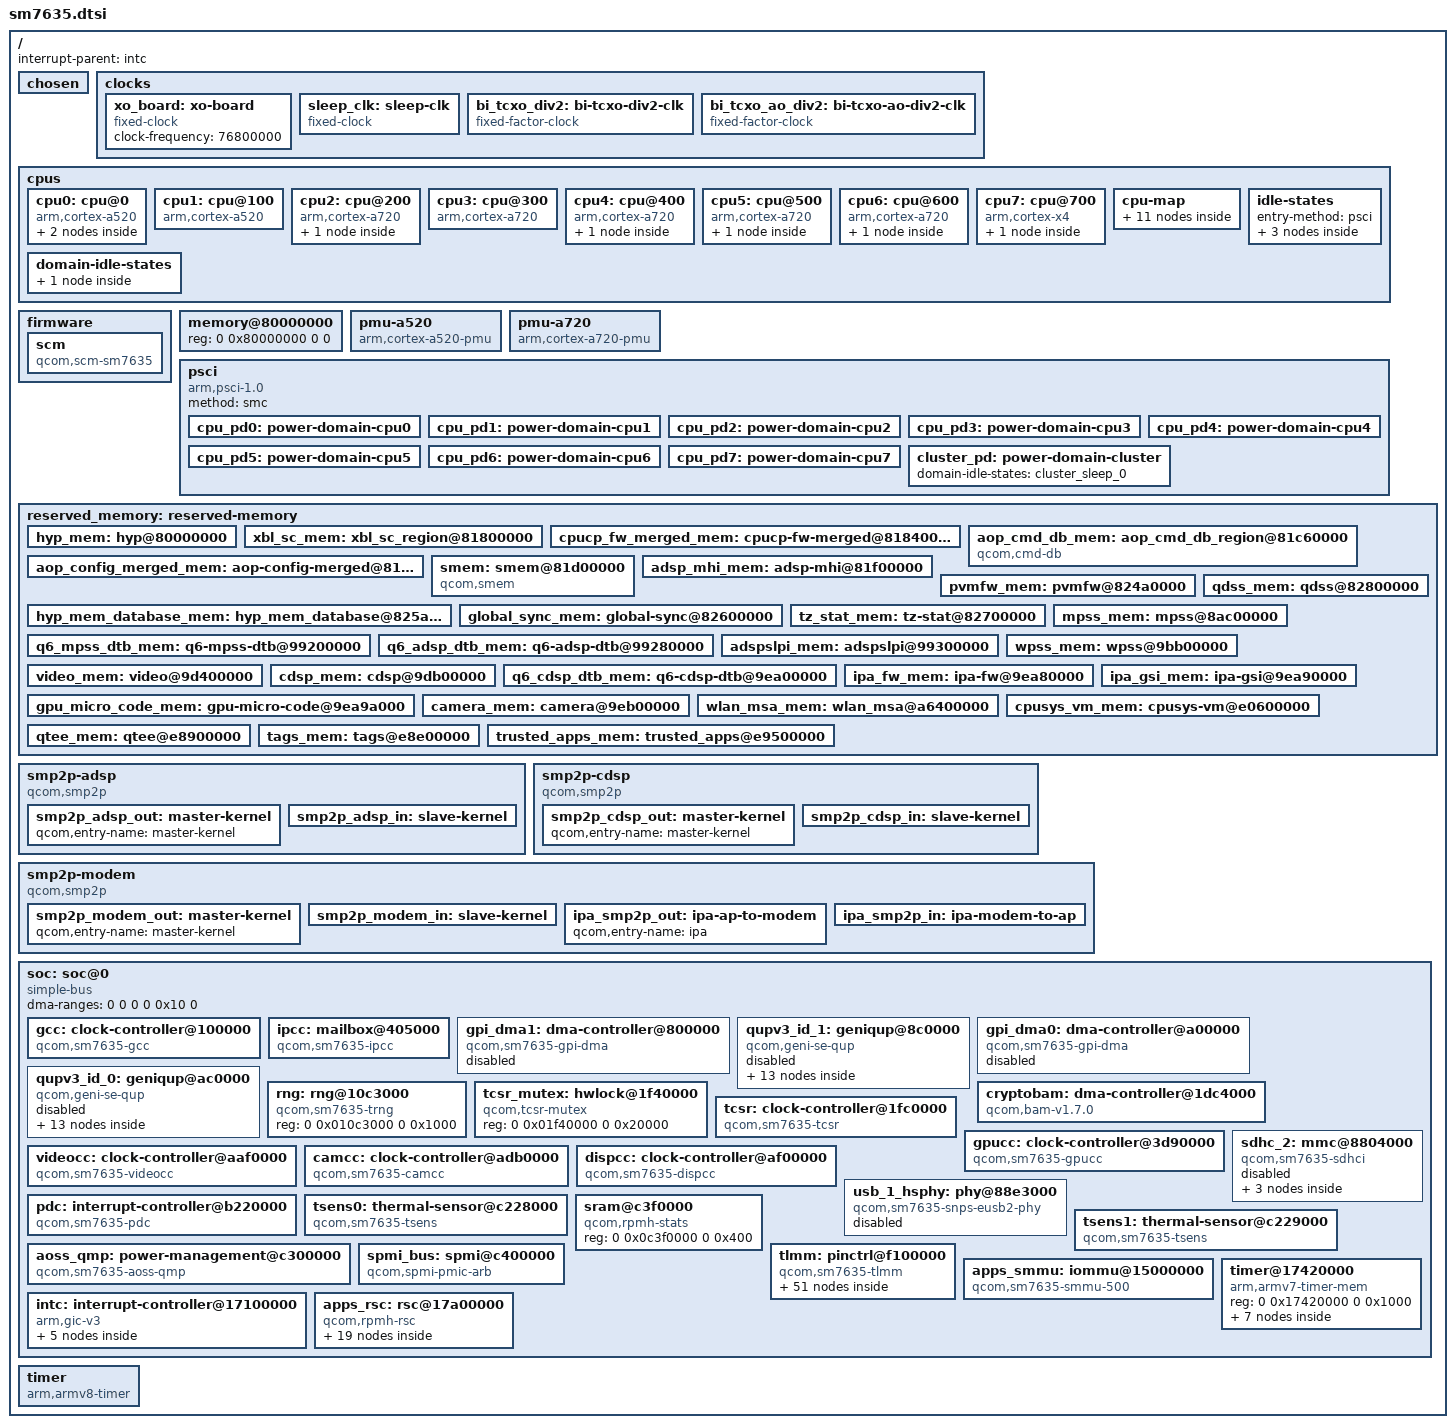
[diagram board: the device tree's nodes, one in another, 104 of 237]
// SPDX-License-Identifier: BSD-3-Clause
/*
 * Copyright (c) 2025, Danila Tikhonov <danila@jiaxyga.com>
 */

#include <dt-bindings/clock/qcom,rpmh.h>

#include <dt-bindings/clock/qcom,sm7635-gcc.h>

#include <dt-bindings/dma/qcom-gpi.h>
#include <dt-bindings/interconnect/qcom,icc.h>
#include <dt-bindings/interrupt-controller/arm-gic.h>
#include <dt-bindings/mailbox/qcom-ipcc.h>
#include <dt-bindings/power/qcom,rpmhpd.h>
#include <dt-bindings/power/qcom-rpmpd.h>
#include <dt-bindings/soc/qcom,gpr.h>
#include <dt-bindings/soc/qcom,rpmh-rsc.h>

/ {
	interrupt-parent = <&intc>;

	#address-cells = <2>;
	#size-cells = <2>;

	chosen { };

	clocks {
		xo_board: xo-board {
			compatible = "fixed-clock";
			clock-frequency = <76800000>;
			#clock-cells = <0>;
		};

		sleep_clk: sleep-clk {
			compatible = "fixed-clock";
			#clock-cells = <0>;
		};

		bi_tcxo_div2: bi-tcxo-div2-clk {
			compatible = "fixed-factor-clock";
			#clock-cells = <0>;

			clocks = <&rpmhcc RPMH_CXO_CLK>;
			clock-mult = <1>;
			clock-div = <2>;
		};

		bi_tcxo_ao_div2: bi-tcxo-ao-div2-clk {
			compatible = "fixed-factor-clock";
			#clock-cells = <0>;

			clocks = <&rpmhcc RPMH_CXO_CLK_A>;
			clock-mult = <1>;
			clock-div = <2>;
		};
	};

	cpus {
		#address-cells = <2>;
		#size-cells = <0>;

		cpu0: cpu@0 {
			device_type = "cpu";
			compatible = "arm,cortex-a520";
			reg = <0 0>;

			power-domains = <&cpu_pd0>;
			power-domain-names = "psci";

			enable-method = "psci";
			next-level-cache = <&l2_0>;

			#cooling-cells = <2>;

			l2_0: l2-cache {
				compatible = "cache";
				cache-level = <2>;
				cache-unified;
				next-level-cache = <&l3_0>;

				l3_0: l3-cache {
					compatible = "cache";
					cache-level = <3>;
					cache-unified;
				};
			};
		};

		cpu1: cpu@100 {
			device_type = "cpu";
			compatible = "arm,cortex-a520";
			reg = <0 0x100>;

			power-domains = <&cpu_pd1>;
			power-domain-names = "psci";

			enable-method = "psci";
			next-level-cache = <&l2_0>;

			//qcom,freq-domain = <&cpufreq_hw 0>;

			#cooling-cells = <2>;
		};

		cpu2: cpu@200 {
			device_type = "cpu";
			compatible = "arm,cortex-a720";
			reg = <0 0x200>;

			power-domains = <&cpu_pd2>;
			power-domain-names = "psci";

			enable-method = "psci";
			next-level-cache = <&l2_200>;

			//qcom,freq-domain = <&cpufreq_hw 3>;

			#cooling-cells = <2>;

			l2_200: l2-cache {
				compatible = "cache";
				cache-level = <2>;
				cache-unified;
				next-level-cache = <&l3_0>;
			};
		};

		cpu3: cpu@300 {
			device_type = "cpu";
			compatible = "arm,cortex-a720";
			reg = <0 0x300>;

			power-domains = <&cpu_pd3>;
			power-domain-names = "psci";

			enable-method = "psci";
			next-level-cache = <&l2_200>;

			//qcom,freq-domain = <&cpufreq_hw 3>;

			#cooling-cells = <2>;
		};

		cpu4: cpu@400 {
			device_type = "cpu";
			compatible = "arm,cortex-a720";
			reg = <0 0x400>;

			power-domains = <&cpu_pd4>;
			power-domain-names = "psci";

			enable-method = "psci";
			next-level-cache = <&l2_400>;

			//qcom,freq-domain = <&cpufreq_hw 3>;

			#cooling-cells = <2>;

			l2_400: l2-cache {
				compatible = "cache";
				cache-level = <2>;
				cache-unified;
				next-level-cache = <&l3_0>;
			};
		};

		cpu5: cpu@500 {
			device_type = "cpu";
			compatible = "arm,cortex-a720";
			reg = <0 0x500>;

			power-domains = <&cpu_pd5>;
			power-domain-names = "psci";

			enable-method = "psci";
			next-level-cache = <&l2_500>;

			//qcom,freq-domain = <&cpufreq_hw 1>;

			#cooling-cells = <2>;

			l2_500: l2-cache {
				compatible = "cache";
				cache-level = <2>;
				cache-unified;
				next-level-cache = <&l3_0>;
			};
		};

		cpu6: cpu@600 {
			device_type = "cpu";
			compatible = "arm,cortex-a720";
			reg = <0 0x600>;

			power-domains = <&cpu_pd6>;
			power-domain-names = "psci";

			enable-method = "psci";
			next-level-cache = <&l2_600>;

			//qcom,freq-domain = <&cpufreq_hw 1>;

			#cooling-cells = <2>;

			l2_600: l2-cache {
				compatible = "cache";
				cache-level = <2>;
				cache-unified;
				next-level-cache = <&l3_0>;
			};
		};

		cpu7: cpu@700 {
			device_type = "cpu";
			compatible = "arm,cortex-x4";
			reg = <0 0x700>;

			power-domains = <&cpu_pd7>;
			power-domain-names = "psci";

			enable-method = "psci";
			next-level-cache = <&l2_700>;

			//qcom,freq-domain = <&cpufreq_hw 2>;

			#cooling-cells = <2>;

			l2_700: l2-cache {
				compatible = "cache";
				cache-level = <2>;
				cache-unified;
				next-level-cache = <&l3_0>;
			};
		};

		cpu-map {
			cluster0 {
				core0 {
					cpu = <&cpu0>;
				};

				core1 {
					cpu = <&cpu1>;
				};

				core2 {
					cpu = <&cpu2>;
				};

				core3 {
					cpu = <&cpu3>;
				};
			};

			cluster1 {
				core0 {
					cpu = <&cpu4>;
				};

				core1 {
					cpu = <&cpu5>;
				};

				core2 {
					cpu = <&cpu6>;
				};
			};

			cluster2 {
				core0 {
					cpu = <&cpu7>;
				};
			};
		};

		idle-states {
			entry-method = "psci";

			silver_cpu_sleep_0: cpu-sleep-0-0 {
				compatible = "arm,idle-state";
				idle-state-name = "silver-rail-power-collapse";
				arm,psci-suspend-param = <0x40000004>;
				entry-latency-us = <550>;
				exit-latency-us = <750>;
				min-residency-us = <6700>;
				local-timer-stop;
			};

			gold_cpu_sleep_0: cpu-sleep-1-0 {
				compatible = "arm,idle-state";
				idle-state-name = "gold-rail-power-collapse";
				arm,psci-suspend-param = <0x40000004>;
				entry-latency-us = <600>;
				exit-latency-us = <1300>;
				min-residency-us = <8136>;
				local-timer-stop;
			};

			gold_plus_cpu_sleep_0: cpu-sleep-2-0 {
				compatible = "arm,idle-state";
				idle-state-name = "gold-plus-rail-power-collapse";
				arm,psci-suspend-param = <0x40000004>;
				entry-latency-us = <600>;
				exit-latency-us = <1500>;
				min-residency-us = <8551>;
				local-timer-stop;
			};
		};

		domain-idle-states {
			cluster_sleep_0: cluster-sleep-0 {
				compatible = "domain-idle-state";
				arm,psci-suspend-param = <0x41000044>;
				entry-latency-us = <750>;
				exit-latency-us = <2350>;
				min-residency-us = <9144>;
			};
		};
	};

	firmware {
		scm: scm {
			compatible = "qcom,scm-sm7635", "qcom,scm";
		};
	};

	memory@80000000 {
		device_type = "memory";
		/* We expect the bootloader to fill in the size */
		reg = <0 0x80000000 0 0>;
	};

	pmu-a520 {
		compatible = "arm,cortex-a520-pmu";
		interrupts = <GIC_PPI 7 IRQ_TYPE_LEVEL_LOW &ppi_cluster0>;
	};

	pmu-a720 {
		compatible = "arm,cortex-a720-pmu";
		interrupts = <GIC_PPI 7 IRQ_TYPE_LEVEL_LOW &ppi_cluster1>;
	};

	psci {
		compatible = "arm,psci-1.0";
		method = "smc";

		cpu_pd0: power-domain-cpu0 {
			#power-domain-cells = <0>;
			power-domains = <&cluster_pd>;
			domain-idle-states = <&silver_cpu_sleep_0>;
		};

		cpu_pd1: power-domain-cpu1 {
			#power-domain-cells = <0>;
			power-domains = <&cluster_pd>;
			domain-idle-states = <&silver_cpu_sleep_0>;
		};

		cpu_pd2: power-domain-cpu2 {
			#power-domain-cells = <0>;
			power-domains = <&cluster_pd>;
			domain-idle-states = <&silver_cpu_sleep_0>;
		};

		cpu_pd3: power-domain-cpu3 {
			#power-domain-cells = <0>;
			power-domains = <&cluster_pd>;
			domain-idle-states = <&silver_cpu_sleep_0>;
		};

		cpu_pd4: power-domain-cpu4 {
			#power-domain-cells = <0>;
			power-domains = <&cluster_pd>;
			domain-idle-states = <&gold_cpu_sleep_0>;
		};

		cpu_pd5: power-domain-cpu5 {
			#power-domain-cells = <0>;
			power-domains = <&cluster_pd>;
			domain-idle-states = <&gold_cpu_sleep_0>;
		};

		cpu_pd6: power-domain-cpu6 {
			#power-domain-cells = <0>;
			power-domains = <&cluster_pd>;
			domain-idle-states = <&gold_cpu_sleep_0>;
		};

		cpu_pd7: power-domain-cpu7 {
			#power-domain-cells = <0>;
			power-domains = <&cluster_pd>;
			domain-idle-states = <&gold_plus_cpu_sleep_0>;
		};

		cluster_pd: power-domain-cluster {
			#power-domain-cells = <0>;
			domain-idle-states = <&cluster_sleep_0>;
		};
	};

	reserved_memory: reserved-memory {
		#address-cells = <2>;
		#size-cells = <2>;
		ranges;

		hyp_mem: hyp@80000000 {
			reg = <0 0x80000000 0 0xe00000>;
			no-map;
		};

		xbl_sc_mem: xbl_sc_region@81800000 {
			reg = <0x0 0x81800000 0x0 0x40000>;
			no-map;
		};

		/*
		 * Merged regions:
		 * - cpucp_fw: 0x81840000 - 0x81a00000
		 * - xbl_dtlog: 0x81a00000 - 0x81a40000
		 * - xbl_ramdump: 0x81a40000 - 0x81c00000
		 * - aop_image:  0x81c00000 - 0x81c60000
		 */
		 cpucp_fw_merged_mem: cpucp-fw-merged@81840000 {
			reg = <0 0x81840000 0 0x420000>;
			no-map;
		};

		aop_cmd_db_mem: aop_cmd_db_region@81c60000 {
			compatible = "qcom,cmd-db";
			reg = <0 0x81c60000 0 0x20000>;
			no-map;
		};

		/*
		 * Merged regions:
		 * - aop_config: 0x81c80000 - 0x81ca0000
		 * - tme_crash_dump: 0x81ca0000 - 0x81ce0000
		 * - tme_log: 0x81ce0000 - 0x81ce4000
		 * - uefi_log: 0x81ce4000 - 0x81cf4000
		 * - chipinfo: 0x81cf4000 - 0x81cf5000
		 */
		aop_config_merged_mem: aop-config-merged@81c80000 {
			reg = <0 0x81c80000 0 0x65000>;
			no-map;
		};

		/* Secdata region can be reused by apps */

		smem: smem@81d00000 {
			compatible = "qcom,smem";
			reg = <0 0x81d00000 0 0x200000>;
			hwlocks = <&tcsr_mutex 3>;
			no-map;
		};

		adsp_mhi_mem: adsp-mhi@81f00000 {
			reg = <0 0x81f00000 0 0x20000>;
			no-map;
		};

		pvmfw_mem: pvmfw@824a0000 {
			reg = <0 0x824a0000 0 0x100000>;
			no-map;
		};

		hyp_mem_database_mem: hyp_mem_database@825a0000 {
			reg = <0 0x825a0000 0 0x60000>;
			no-map;
		};

		global_sync_mem: global-sync@82600000 {
			reg = <0 0x82600000 0 0x100000>;
			no-map;
		};

		tz_stat_mem: tz-stat@82700000 {
			reg = <0 0x82700000 0 0x100000>;
			no-map;
		};

		qdss_mem: qdss@82800000 {
			reg = <0 0x82800000 0 0x2000000>;
			no-map;
		};

		mpss_mem: mpss@8ac00000 {
			reg = <0 0x8ac00000 0 0xe600000>;
			no-map;
		};

		q6_mpss_dtb_mem: q6-mpss-dtb@99200000 {
			reg = <0 0x99200000 0 0x80000>;
			no-map;
		};

		q6_adsp_dtb_mem: q6-adsp-dtb@99280000 {
			reg = <0 0x99280000 0 0x80000>;
			no-map;
		};

		adspslpi_mem: adspslpi@99300000 {
			reg = <0 0x99300000 0 0x2800000>;
			no-map;
		};

		wpss_mem: wpss@9bb00000 {
			reg = <0 0x9bb00000 0 0x1900000>;
			no-map;
		};

		video_mem: video@9d400000 {
			reg = <0 0x9d400000 0 0x700000>;
			no-map;
		};

		cdsp_mem: cdsp@9db00000 {
			reg = <0 0x9db00000 0 0xf00000>;
			no-map;
		};

		q6_cdsp_dtb_mem: q6-cdsp-dtb@9ea00000 {
			reg = <0 0x9ea00000 0 0x80000>;
			no-map;
		};

		ipa_fw_mem: ipa-fw@9ea80000 {
			reg = <0 0x9ea80000 0 0x10000>;
			no-map;
		};

		ipa_gsi_mem: ipa-gsi@9ea90000 {
			reg = <0 0x9ea90000 0 0xa000>;
			no-map;
		};

		gpu_micro_code_mem: gpu-micro-code@9ea9a000 {
			reg = <0 0x9ea9a000 0 0x2000>;
			no-map;
		};

		camera_mem: camera@9eb00000 {
			reg = <0 0x9eb00000 0 0x800000>;
			no-map;
		};

		wlan_msa_mem: wlan_msa@a6400000 {
			reg = <0 0xa6400000 0 0xc00000>;
			no-map;
		};

		cpusys_vm_mem: cpusys-vm@e0600000 {
			reg = <0 0xe0600000 0 0x400000>;
			no-map;
		};

		qtee_mem: qtee@e8900000 {
			reg = <0 0xe8900000 0 0x500000>;
			no-map;
		};

		tags_mem: tags@e8e00000 {
			reg = <0 0xe8e00000 0 0x700000>;
			no-map;
		};

		trusted_apps_mem: trusted_apps@e9500000 {
			/* TODO: Remove me?*/
			reg = <0 0xe9500000 0 0x1200000>;
			no-map;
		};
	};

	smp2p-adsp {
		compatible = "qcom,smp2p";

		interrupts-extended = <&ipcc IPCC_CLIENT_LPASS
					     IPCC_MPROC_SIGNAL_SMP2P
					     IRQ_TYPE_EDGE_RISING>;

		mboxes = <&ipcc IPCC_CLIENT_LPASS
				IPCC_MPROC_SIGNAL_SMP2P>;

		qcom,smem = <443>, <429>;
		qcom,local-pid = <0>;
		qcom,remote-pid = <2>;

		smp2p_adsp_out: master-kernel {
			qcom,entry-name = "master-kernel";
			#qcom,smem-state-cells = <1>;
		};

		smp2p_adsp_in: slave-kernel {
			qcom,entry-name = "slave-kernel";
			interrupt-controller;
			#interrupt-cells = <2>;
		};
	};

	smp2p-cdsp {
		compatible = "qcom,smp2p";

		interrupts-extended = <&ipcc IPCC_CLIENT_CDSP
					     IPCC_MPROC_SIGNAL_SMP2P
					     IRQ_TYPE_EDGE_RISING>;

		mboxes = <&ipcc IPCC_CLIENT_CDSP
				IPCC_MPROC_SIGNAL_SMP2P>;

		qcom,smem = <94>, <432>;
		qcom,local-pid = <0>;
		qcom,remote-pid = <5>;

		smp2p_cdsp_out: master-kernel {
			qcom,entry-name = "master-kernel";
			#qcom,smem-state-cells = <1>;
		};

		smp2p_cdsp_in: slave-kernel {
			qcom,entry-name = "slave-kernel";
			interrupt-controller;
			#interrupt-cells = <2>;
		};
	};

	smp2p-modem {
		compatible = "qcom,smp2p";

		interrupts-extended = <&ipcc IPCC_CLIENT_MPSS
					     IPCC_MPROC_SIGNAL_SMP2P
					     IRQ_TYPE_EDGE_RISING>;

		mboxes = <&ipcc IPCC_CLIENT_MPSS
				IPCC_MPROC_SIGNAL_SMP2P>;

		qcom,smem = <435>, <428>;
		qcom,local-pid = <0>;
		qcom,remote-pid = <1>;

		smp2p_modem_out: master-kernel {
			qcom,entry-name = "master-kernel";
			#qcom,smem-state-cells = <1>;
		};

		smp2p_modem_in: slave-kernel {
			qcom,entry-name = "slave-kernel";
			interrupt-controller;
			#interrupt-cells = <2>;
		};

		ipa_smp2p_out: ipa-ap-to-modem {
			qcom,entry-name = "ipa";
			#qcom,smem-state-cells = <1>;
		};

		/* ipa - inbound entry from mss */
		ipa_smp2p_in: ipa-modem-to-ap {
			qcom,entry-name = "ipa";
			interrupt-controller;
			#interrupt-cells = <2>;
		};
	};

	soc: soc@0 {
		compatible = "simple-bus";

		#address-cells = <2>;
		#size-cells = <2>;
		dma-ranges = <0 0 0 0 0x10 0>;
		ranges = <0 0 0 0 0x10 0>;

		gcc: clock-controller@100000 {
			compatible = "qcom,sm7635-gcc";
			reg = <0 0x00100000 0 0x1f4200>;

			clocks = <&bi_tcxo_div2>,
				 <0>, <0>, <0>, <0>, <0>, <0>;
				 /*<&pcie0_phy QMP_PCIE_PIPE_CLK>,
				 <&pcie1_phy QMP_PCIE_PIPE_CLK>
				 <&ufs_mem_phy 0>,
				 <&ufs_mem_phy 1>,
				 <&ufs_mem_phy 2>,
				 <&usb_dp_qmpphy QMP_USB43DP_USB3_PIPE_CLK>;*/
			power-domains = <&rpmhpd RPMHPD_CX>;

			#clock-cells = <1>;
			#reset-cells = <1>;
			#power-domain-cells = <1>;
		};

		ipcc: mailbox@405000 {
			compatible = "qcom,sm7635-ipcc",
				     "qcom,ipcc";
			reg = <0 0x00405000 0 0x1000>;

			interrupts = <GIC_SPI 229 IRQ_TYPE_LEVEL_HIGH 0>;
			interrupt-controller;
			#interrupt-cells = <3>;

			#mbox-cells = <2>;
		};

		gpi_dma1: dma-controller@800000 {
			compatible = "qcom,sm7635-gpi-dma",
				     "qcom,sm6350-gpi-dma";
			reg = <0 0x00800000 0 0x60000>;

			interrupts = <GIC_SPI 588 IRQ_TYPE_LEVEL_HIGH 0>,
				     <GIC_SPI 589 IRQ_TYPE_LEVEL_HIGH 0>,
				     <GIC_SPI 590 IRQ_TYPE_LEVEL_HIGH 0>,
				     <GIC_SPI 591 IRQ_TYPE_LEVEL_HIGH 0>,
				     <GIC_SPI 592 IRQ_TYPE_LEVEL_HIGH 0>,
				     <GIC_SPI 593 IRQ_TYPE_LEVEL_HIGH 0>,
				     <GIC_SPI 594 IRQ_TYPE_LEVEL_HIGH 0>,
				     <GIC_SPI 595 IRQ_TYPE_LEVEL_HIGH 0>,
				     <GIC_SPI 351 IRQ_TYPE_LEVEL_HIGH 0>,
				     <GIC_SPI 352 IRQ_TYPE_LEVEL_HIGH 0>,
				     <GIC_SPI 353 IRQ_TYPE_LEVEL_HIGH 0>,
				     <GIC_SPI 354 IRQ_TYPE_LEVEL_HIGH 0>,
				     <GIC_SPI 355 IRQ_TYPE_LEVEL_HIGH 0>;

			dma-channels = <12>;
			dma-channel-mask = <0x3f>;
			#dma-cells = <3>;

			iommus = <&apps_smmu 0x36 0>;

			dma-coherent;

			status = "disabled";
		};

		qupv3_id_1: geniqup@8c0000 {
			compatible = "qcom,geni-se-qup";
			reg = <0 0x008c0000 0 0x2000>;

			clocks = <&gcc GCC_QUPV3_WRAP_1_M_AHB_CLK>,
				 <&gcc GCC_QUPV3_WRAP_1_S_AHB_CLK>;
			clock-names = "m-ahb",
				      "s-ahb";

			iommus = <&apps_smmu 0x23 0>;

			dma-coherent;

			#address-cells = <2>;
			#size-cells = <2>;
			ranges;

			status = "disabled";

			i2c7: i2c@880000 {
				compatible = "qcom,geni-i2c";
				reg = <0 0x00880000 0 0x4000>;

				interrupts = <GIC_SPI 373 IRQ_TYPE_LEVEL_HIGH 0>;

				clocks = <&gcc GCC_QUPV3_WRAP1_S0_CLK>;
				clock-names = "se";

				/* TODO: Interconnects */

				power-domains = <&rpmhpd RPMHPD_CX>;

				/* TODO: operating-points-v2 */

				dmas = <&gpi_dma1 0 0 QCOM_GPI_I2C>,
				       <&gpi_dma1 1 0 QCOM_GPI_I2C>;
				dma-names = "tx",
					    "rx";

				pinctrl-0 = <&qup_i2c7_data_clk>;
				pinctrl-names = "default";

				#address-cells = <1>;
				#size-cells = <0>;

				status = "disabled";
			};

			spi7: spi@880000 {
				compatible = "qcom,geni-spi";
				reg = <0 0x00880000 0 0x4000>;

				interrupts = <GIC_SPI 373 IRQ_TYPE_LEVEL_HIGH 0>;

				clocks = <&gcc GCC_QUPV3_WRAP1_S0_CLK>;
				clock-names = "se";

				/* TODO: Interconnects */

				power-domains = <&rpmhpd RPMHPD_CX>;

				/* TODO: operating-points-v2 */

				dmas = <&gpi_dma1 0 0 QCOM_GPI_SPI>,
				       <&gpi_dma1 1 0 QCOM_GPI_SPI>;
				dma-names = "tx",
					    "rx";

				pinctrl-0 = <&qup_spi7_data_clk>,
					    <&qup_spi7_cs>;
				pinctrl-names = "default";

				#address-cells = <1>;
				#size-cells = <0>;

				status = "disabled";
			};

			i2c8: i2c@884000 {
				compatible = "qcom,geni-i2c";
				reg = <0 0x00884000 0 0x4000>;

				interrupts = <GIC_SPI 583 IRQ_TYPE_LEVEL_HIGH 0>;

				clocks = <&gcc GCC_QUPV3_WRAP1_S1_CLK>;
				clock-names = "se";

				/* TODO: Interconnects */

				power-domains = <&rpmhpd RPMHPD_CX>;

				/* TODO: operating-points-v2 */

				dmas = <&gpi_dma1 0 1 QCOM_GPI_I2C>,
				       <&gpi_dma1 1 1 QCOM_GPI_I2C>;
				dma-names = "tx",
					    "rx";

				pinctrl-0 = <&qup_i2c8_data_clk>;
				pinctrl-names = "default";

				#address-cells = <1>;
				#size-cells = <0>;

				status = "disabled";
			};

			spi8: spi@884000 {
				compatible = "qcom,geni-spi";
				reg = <0 0x00884000 0 0x4000>;

				interrupts = <GIC_SPI 583 IRQ_TYPE_LEVEL_HIGH 0>;

				clocks = <&gcc GCC_QUPV3_WRAP1_S1_CLK>;
				clock-names = "se";

				/* TODO: Interconnects */

				power-domains = <&rpmhpd RPMHPD_CX>;

				/* TODO: operating-points-v2 */

				dmas = <&gpi_dma1 0 1 QCOM_GPI_SPI>,
				       <&gpi_dma1 1 1 QCOM_GPI_SPI>;
				dma-names = "tx",
					    "rx";

				pinctrl-0 = <&qup_spi8_data_clk>,
					    <&qup_spi8_cs>;
				pinctrl-names = "default";

				#address-cells = <1>;
				#size-cells = <0>;

				status = "disabled";
			};

			i2c9: i2c@888000 {
				compatible = "qcom,geni-i2c";
				reg = <0 0x00888000 0 0x4000>;

				interrupts = <GIC_SPI 584 IRQ_TYPE_LEVEL_HIGH 0>;

				clocks = <&gcc GCC_QUPV3_WRAP1_S2_CLK>;
				clock-names = "se";

				/* TODO: Interconnects */

				power-domains = <&rpmhpd RPMHPD_CX>;

				/* TODO: operating-points-v2 */

				dmas = <&gpi_dma1 0 2 QCOM_GPI_I2C>,
				       <&gpi_dma1 1 2 QCOM_GPI_I2C>;
				dma-names = "tx",
					    "rx";

				pinctrl-0 = <&qup_i2c9_data_clk>;
				pinctrl-names = "default";

				#address-cells = <1>;
				#size-cells = <0>;

				status = "disabled";
			};

			spi9: spi@888000 {
				compatible = "qcom,geni-spi";
				reg = <0 0x00888000 0 0x4000>;

				interrupts = <GIC_SPI 584 IRQ_TYPE_LEVEL_HIGH 0>;

				clocks = <&gcc GCC_QUPV3_WRAP1_S2_CLK>;
				clock-names = "se";

				/* TODO: Interconnects */

				power-domains = <&rpmhpd RPMHPD_CX>;

				/* TODO: operating-points-v2 */

				dmas = <&gpi_dma1 0 2 QCOM_GPI_SPI>,
				       <&gpi_dma1 1 2 QCOM_GPI_SPI>;
				dma-names = "tx",
					    "rx";

				pinctrl-0 = <&qup_spi9_data_clk>,
					    <&qup_spi9_cs>;
				pinctrl-names = "default";

				#address-cells = <1>;
				#size-cells = <0>;

				status = "disabled";
			};

			i2c10: i2c@88c000 {
				compatible = "qcom,geni-i2c";
				reg = <0 0x0088c000 0 0x4000>;

				interrupts = <GIC_SPI 585 IRQ_TYPE_LEVEL_HIGH 0>;

				clocks = <&gcc GCC_QUPV3_WRAP1_S3_CLK>;
				clock-names = "se";

				/* TODO: Interconnects */

				power-domains = <&rpmhpd RPMHPD_CX>;

				/* TODO: operating-points-v2 */

				dmas = <&gpi_dma1 0 3 QCOM_GPI_I2C>,
				       <&gpi_dma1 1 3 QCOM_GPI_I2C>;
				dma-names = "tx",
					    "rx";

				pinctrl-0 = <&qup_i2c10_data_clk>;
				pinctrl-names = "default";

				#address-cells = <1>;
				#size-cells = <0>;

				status = "disabled";
			};

			spi10: spi@88c000 {
				compatible = "qcom,geni-spi";
				reg = <0 0x0088c000 0 0x4000>;

				interrupts = <GIC_SPI 585 IRQ_TYPE_LEVEL_HIGH 0>;

				clocks = <&gcc GCC_QUPV3_WRAP1_S3_CLK>;
				clock-names = "se";

				/* TODO: Interconnects */

				power-domains = <&rpmhpd RPMHPD_CX>;

				/* TODO: operating-points-v2 */

				dmas = <&gpi_dma1 0 3 QCOM_GPI_SPI>,
				       <&gpi_dma1 1 3 QCOM_GPI_SPI>;
				dma-names = "tx",
					    "rx";

				pinctrl-0 = <&qup_spi10_data_clk>,
					    <&qup_spi10_cs>;
				pinctrl-names = "default";

				#address-cells = <1>;
				#size-cells = <0>;

				status = "disabled";
			};

			uart11: serial@890000 {
				compatible = "qcom,geni-uart";
				reg = <0 0x00890000 0 0x4000>;

				interrupts = <GIC_SPI 586 IRQ_TYPE_LEVEL_HIGH 0>;

				clocks = <&gcc GCC_QUPV3_WRAP1_S4_CLK>;
				clock-names = "se";

				/* TODO: Interconnects */

				power-domains = <&rpmhpd RPMHPD_CX>;

				/* TODO: operating-points-v2 */

				pinctrl-0 = <&qup_uart11_default>,
					    <&qup_uart11_cts_rts>;
				pinctrl-names = "default";

				status = "disabled";
			};

			i2c12: i2c@894000 {
				compatible = "qcom,geni-i2c";
				reg = <0 0x00894000 0 0x4000>;

				interrupts = <GIC_SPI 587 IRQ_TYPE_LEVEL_HIGH 0>;

				clocks = <&gcc GCC_QUPV3_WRAP1_S5_CLK>;
				clock-names = "se";

				/* TODO: Interconnects */

				power-domains = <&rpmhpd RPMHPD_CX>;

				/* TODO: operating-points-v2 */

				dmas = <&gpi_dma1 0 5 QCOM_GPI_I2C>,
				       <&gpi_dma1 1 5 QCOM_GPI_I2C>;
				dma-names = "tx",
					    "rx";

				pinctrl-0 = <&qup_i2c12_data_clk>;
				pinctrl-names = "default";

				#address-cells = <1>;
				#size-cells = <0>;

				status = "disabled";
			};

			spi12: spi@894000 {
				compatible = "qcom,geni-spi";
				reg = <0 0x00894000 0 0x4000>;

				interrupts = <GIC_SPI 587 IRQ_TYPE_LEVEL_HIGH 0>;

				clocks = <&gcc GCC_QUPV3_WRAP1_S5_CLK>;
				clock-names = "se";

				/* TODO: Interconnects */

				power-domains = <&rpmhpd RPMHPD_CX>;

				/* TODO: operating-points-v2 */

				dmas = <&gpi_dma1 0 5 QCOM_GPI_SPI>,
				       <&gpi_dma1 1 5 QCOM_GPI_SPI>;
				dma-names = "tx",
					    "rx";

				pinctrl-0 = <&qup_spi12_data_clk>,
					    <&qup_spi12_cs>;
				pinctrl-names = "default";

				#address-cells = <1>;
				#size-cells = <0>;

				status = "disabled";
			};

			i2c13: i2c@898000 {
				compatible = "qcom,geni-i2c";
				reg = <0 0x00898000 0 0x4000>;

				interrupts = <GIC_SPI 461 IRQ_TYPE_LEVEL_HIGH 0>;

				clocks = <&gcc GCC_QUPV3_WRAP1_S6_CLK>;
				clock-names = "se";

				/* TODO: Interconnects */

				power-domains = <&rpmhpd RPMHPD_CX>;

				/* TODO: operating-points-v2 */

				dmas = <&gpi_dma1 0 6 QCOM_GPI_I2C>,
				       <&gpi_dma1 1 6 QCOM_GPI_I2C>;
				dma-names = "tx",
					    "rx";

				pinctrl-0 = <&qup_i2c13_data_clk>;
				pinctrl-names = "default";

				#address-cells = <1>;
				#size-cells = <0>;

				status = "disabled";
			};

			spi13: spi@898000 {
				compatible = "qcom,geni-spi";
				reg = <0 0x00898000 0 0x4000>;

				interrupts = <GIC_SPI 461 IRQ_TYPE_LEVEL_HIGH 0>;

				clocks = <&gcc GCC_QUPV3_WRAP1_S6_CLK>;
				clock-names = "se";

				/* TODO: Interconnects */

				power-domains = <&rpmhpd RPMHPD_CX>;

				/* TODO: operating-points-v2 */

				dmas = <&gpi_dma1 0 6 QCOM_GPI_SPI>,
				       <&gpi_dma1 1 6 QCOM_GPI_SPI>;
				dma-names = "tx",
					    "rx";

				pinctrl-0 = <&qup_spi13_data_clk>,
					    <&qup_spi13_cs>;
				pinctrl-names = "default";

				#address-cells = <1>;
				#size-cells = <0>;

				status = "disabled";
			};
		};

		gpi_dma0: dma-controller@a00000 {
			compatible = "qcom,sm7635-gpi-dma",
				     "qcom,sm6350-gpi-dma";
			reg = <0 0x00a00000 0 0x60000>;

			interrupts = <GIC_SPI 433 IRQ_TYPE_LEVEL_HIGH 0>,
				     <GIC_SPI 434 IRQ_TYPE_LEVEL_HIGH 0>,
				     <GIC_SPI 435 IRQ_TYPE_LEVEL_HIGH 0>,
				     <GIC_SPI 436 IRQ_TYPE_LEVEL_HIGH 0>,
				     <GIC_SPI 437 IRQ_TYPE_LEVEL_HIGH 0>,
				     <GIC_SPI 438 IRQ_TYPE_LEVEL_HIGH 0>,
				     <GIC_SPI 439 IRQ_TYPE_LEVEL_HIGH 0>,
				     <GIC_SPI 595 IRQ_TYPE_LEVEL_HIGH 0>,
				     <GIC_SPI 596 IRQ_TYPE_LEVEL_HIGH 0>,
				     <GIC_SPI 597 IRQ_TYPE_LEVEL_HIGH 0>,
				     <GIC_SPI 598 IRQ_TYPE_LEVEL_HIGH 0>,
				     <GIC_SPI 599 IRQ_TYPE_LEVEL_HIGH 0>;

			dma-channels = <12>;
			dma-channel-mask = <0x3e>;
			#dma-cells = <3>;

			iommus = <&apps_smmu 0x576 0>;

			dma-coherent;

			status = "disabled";
		};

		qupv3_id_0: geniqup@ac0000 {
			compatible = "qcom,geni-se-qup";
			reg = <0 0x00ac0000 0 0x2000>;

			clocks = <&gcc GCC_QUPV3_WRAP_0_M_AHB_CLK>,
				 <&gcc GCC_QUPV3_WRAP_0_S_AHB_CLK>;
			clock-names = "m-ahb",
				      "s-ahb";

			/* TODO: Interconnects */

			iommus = <&apps_smmu 0x563 0>;

			dma-coherent;

			#address-cells = <2>;
			#size-cells = <2>;
			ranges;

			status = "disabled";

			i2c0: i2c@a80000 {
				compatible = "qcom,geni-i2c";
				reg = <0 0x00a80000 0 0x4000>;

				interrupts = <GIC_SPI 520 IRQ_TYPE_LEVEL_HIGH 0>;

				clocks = <&gcc GCC_QUPV3_WRAP0_S0_CLK>;
				clock-names = "se";

				/* TODO: Interconnects */

				power-domains = <&rpmhpd RPMHPD_CX>;

				/* TODO: operating-points-v2 */

				dmas = <&gpi_dma0 0 0 QCOM_GPI_I2C>,
				       <&gpi_dma0 1 0 QCOM_GPI_I2C>;
				dma-names = "tx",
					    "rx";

				pinctrl-0 = <&qup_i2c0_data_clk>;
				pinctrl-names = "default";

				#address-cells = <1>;
				#size-cells = <0>;

				status = "disabled";
			};

			spi0: spi@a80000 {
				compatible = "qcom,geni-spi";
				reg = <0 0x00a80000 0 0x4000>;

				interrupts = <GIC_SPI 520 IRQ_TYPE_LEVEL_HIGH 0>;

				clocks = <&gcc GCC_QUPV3_WRAP0_S0_CLK>;
				clock-names = "se";

				/* TODO: Interconnects */

				power-domains = <&rpmhpd RPMHPD_CX>;

				/* TODO: operating-points-v2 */

				dmas = <&gpi_dma0 0 0 QCOM_GPI_SPI>,
				       <&gpi_dma0 1 0 QCOM_GPI_SPI>;
				dma-names = "tx",
					    "rx";

				pinctrl-0 = <&qup_spi0_data_clk>,
					    <&qup_spi0_cs>;
				pinctrl-names = "default";

				#address-cells = <1>;
				#size-cells = <0>;

				status = "disabled";
			};

			i2c1: i2c@a84000 {
				compatible = "qcom,geni-i2c";
				reg = <0 0x00a84000 0 0x4000>;

				interrupts = <GIC_SPI 521 IRQ_TYPE_LEVEL_HIGH 0>;

				clocks = <&gcc GCC_QUPV3_WRAP0_S1_CLK>;
				clock-names = "se";

				/* TODO: Interconnects */

				power-domains = <&rpmhpd RPMHPD_CX>;

				/* TODO: operating-points-v2 */

				dmas = <&gpi_dma0 0 1 QCOM_GPI_I2C>,
				       <&gpi_dma0 1 1 QCOM_GPI_I2C>;
				dma-names = "tx",
					    "rx";

				pinctrl-0 = <&qup_i2c1_data_clk>;
				pinctrl-names = "default";

				#address-cells = <1>;
				#size-cells = <0>;

				status = "disabled";
			};

			spi1: spi@a84000 {
				compatible = "qcom,geni-spi";
				reg = <0 0x00a84000 0 0x4000>;

				interrupts = <GIC_SPI 521 IRQ_TYPE_LEVEL_HIGH 0>;

				clocks = <&gcc GCC_QUPV3_WRAP0_S1_CLK>;
				clock-names = "se";

				/* TODO: Interconnects */

				power-domains = <&rpmhpd RPMHPD_CX>;

				/* TODO: operating-points-v2 */

				dmas = <&gpi_dma0 0 1 QCOM_GPI_SPI>,
				       <&gpi_dma0 1 1 QCOM_GPI_SPI>;
				dma-names = "tx",
					    "rx";

				pinctrl-0 = <&qup_spi1_data_clk>,
					    <&qup_spi1_cs>;
				pinctrl-names = "default";

				#address-cells = <1>;
				#size-cells = <0>;

				status = "disabled";
			};

			i2c2: i2c@a88000 {
				compatible = "qcom,geni-i2c";
				reg = <0 0x00a88000 0 0x4000>;

				interrupts = <GIC_SPI 522 IRQ_TYPE_LEVEL_HIGH 0>;

				clocks = <&gcc GCC_QUPV3_WRAP0_S2_CLK>;
				clock-names = "se";

				/* TODO: Interconnects */

				power-domains = <&rpmhpd RPMHPD_CX>;

				/* TODO: operating-points-v2 */

				dmas = <&gpi_dma0 0 2 QCOM_GPI_I2C>,
				       <&gpi_dma0 1 2 QCOM_GPI_I2C>;
				dma-names = "tx",
					    "rx";

				pinctrl-0 = <&qup_i2c2_data_clk>;
				pinctrl-names = "default";

				#address-cells = <1>;
				#size-cells = <0>;

				status = "disabled";
			};

			spi2: spi@a88000 {
				compatible = "qcom,geni-spi";
				reg = <0 0x00a88000 0 0x4000>;

				interrupts = <GIC_SPI 522 IRQ_TYPE_LEVEL_HIGH 0>;

				clocks = <&gcc GCC_QUPV3_WRAP0_S2_CLK>;
				clock-names = "se";

				/* TODO: Interconnects */

				power-domains = <&rpmhpd RPMHPD_CX>;

				/* TODO: operating-points-v2 */

				dmas = <&gpi_dma0 0 2 QCOM_GPI_SPI>,
				       <&gpi_dma0 1 2 QCOM_GPI_SPI>;
				dma-names = "tx",
					    "rx";

				pinctrl-0 = <&qup_spi2_data_clk>,
					    <&qup_spi2_cs>;
				pinctrl-names = "default";

				#address-cells = <1>;
				#size-cells = <0>;

				status = "disabled";
			};

			i2c3: i2c@a8c000 {
				compatible = "qcom,geni-i2c";
				reg = <0 0x00a8c000 0 0x4000>;

				interrupts = <GIC_SPI 523 IRQ_TYPE_LEVEL_HIGH 0>;

				clocks = <&gcc GCC_QUPV3_WRAP0_S3_CLK>;
				clock-names = "se";

				/* TODO: Interconnects */

				power-domains = <&rpmhpd RPMHPD_CX>;

				/* TODO: operating-points-v2 */

				dmas = <&gpi_dma0 0 3 QCOM_GPI_I2C>,
				       <&gpi_dma0 1 3 QCOM_GPI_I2C>;
				dma-names = "tx",
					    "rx";

				pinctrl-0 = <&qup_i2c3_data_clk>;
				pinctrl-names = "default";

				#address-cells = <1>;
				#size-cells = <0>;

				status = "disabled";
			};

			spi3: spi@a8c000 {
				compatible = "qcom,geni-spi";
				reg = <0 0x00a8c000 0 0x4000>;

				interrupts = <GIC_SPI 523 IRQ_TYPE_LEVEL_HIGH 0>;

				clocks = <&gcc GCC_QUPV3_WRAP0_S3_CLK>;
				clock-names = "se";

				/* TODO: Interconnects */

				power-domains = <&rpmhpd RPMHPD_CX>;

				/* TODO: operating-points-v2 */

				dmas = <&gpi_dma0 0 3 QCOM_GPI_SPI>,
				       <&gpi_dma0 1 3 QCOM_GPI_SPI>;
				dma-names = "tx",
					    "rx";

				pinctrl-0 = <&qup_spi3_data_clk>,
					    <&qup_spi3_cs>;
				pinctrl-names = "default";

				#address-cells = <1>;
				#size-cells = <0>;

				status = "disabled";
			};

			i2c4: i2c@a90000 {
				compatible = "qcom,geni-i2c";
				reg = <0 0x00a90000 0 0x4000>;

				interrupts = <GIC_SPI 524 IRQ_TYPE_LEVEL_HIGH 0>;

				clocks = <&gcc GCC_QUPV3_WRAP0_S4_CLK>;
				clock-names = "se";

				/* TODO: Interconnects */

				power-domains = <&rpmhpd RPMHPD_CX>;

				/* TODO: operating-points-v2 */

				dmas = <&gpi_dma0 0 4 QCOM_GPI_I2C>,
				       <&gpi_dma0 1 4 QCOM_GPI_I2C>;
				dma-names = "tx",
					    "rx";

				pinctrl-0 = <&qup_i2c4_data_clk>;
				pinctrl-names = "default";

				#address-cells = <1>;
				#size-cells = <0>;

				status = "disabled";
			};

			spi4: spi@a90000 {
				compatible = "qcom,geni-spi";
				reg = <0 0x00a90000 0 0x4000>;

				interrupts = <GIC_SPI 524 IRQ_TYPE_LEVEL_HIGH 0>;

				clocks = <&gcc GCC_QUPV3_WRAP0_S4_CLK>;
				clock-names = "se";

				/* TODO: Interconnects */

				power-domains = <&rpmhpd RPMHPD_CX>;

				/* TODO: operating-points-v2 */

				dmas = <&gpi_dma0 0 4 QCOM_GPI_SPI>,
				       <&gpi_dma0 1 4 QCOM_GPI_SPI>;
				dma-names = "tx",
					    "rx";

				pinctrl-0 = <&qup_spi4_data_clk>,
					    <&qup_spi4_cs>;
				pinctrl-names = "default";

				#address-cells = <1>;
				#size-cells = <0>;

				status = "disabled";
			};

			uart5: serial@a94000 {
				compatible = "qcom,geni-uart";
				reg = <0 0x00a94000 0 0x4000>;

				interrupts = <GIC_SPI 525 IRQ_TYPE_LEVEL_HIGH 0>;

				clocks = <&gcc GCC_QUPV3_WRAP0_S5_CLK>;
				clock-names = "se";

				/* TODO: Interconnects */

				power-domains = <&rpmhpd RPMHPD_CX>;

				/* TODO: operating-points-v2 */

				pinctrl-0 = <&qup_uart5_default>;
				pinctrl-names = "default";

				status = "disabled";
			};

			i2c6: i2c@a98000 {
				compatible = "qcom,geni-i2c";
				reg = <0 0x00a98000 0 0x4000>;

				interrupts = <GIC_SPI 526 IRQ_TYPE_LEVEL_HIGH 0>;

				clocks = <&gcc GCC_QUPV3_WRAP0_S6_CLK>;
				clock-names = "se";

				/* TODO: Interconnects */

				power-domains = <&rpmhpd RPMHPD_CX>;

				/* TODO: operating-points-v2 */

				dmas = <&gpi_dma0 0 6 QCOM_GPI_I2C>,
				       <&gpi_dma0 1 6 QCOM_GPI_I2C>;
				dma-names = "tx",
					    "rx";

				pinctrl-0 = <&qup_i2c6_data_clk>;
				pinctrl-names = "default";

				#address-cells = <1>;
				#size-cells = <0>;

				status = "disabled";
			};

			spi6: spi@a98000 {
				compatible = "qcom,geni-spi";
				reg = <0 0x00a98000 0 0x4000>;

				interrupts = <GIC_SPI 526 IRQ_TYPE_LEVEL_HIGH 0>;

				clocks = <&gcc GCC_QUPV3_WRAP0_S6_CLK>;
				clock-names = "se";

				/* TODO: Interconnects */

				power-domains = <&rpmhpd RPMHPD_CX>;

				/* TODO: operating-points-v2 */

				dmas = <&gpi_dma0 0 6 QCOM_GPI_SPI>,
				       <&gpi_dma0 1 6 QCOM_GPI_SPI>;
				dma-names = "tx",
					    "rx";

				pinctrl-0 = <&qup_spi6_data_clk>,
					    <&qup_spi6_cs>;
				pinctrl-names = "default";

				#address-cells = <1>;
				#size-cells = <0>;

				status = "disabled";
			};
		};

		rng: rng@10c3000 {
			compatible = "qcom,sm7635-trng",
				     "qcom,trng";
			reg = <0 0x010c3000 0 0x1000>;
		};

		cryptobam: dma-controller@1dc4000 {
			compatible = "qcom,bam-v1.7.0";
			reg = <0 0x01dc4000 0 0x28000>;

			/* TODO: Interconnects */

			interrupts = <GIC_SPI 272 IRQ_TYPE_LEVEL_HIGH 0>;

			#dma-cells = <1>;

			iommus = <&apps_smmu 0x480 0>,
				 <&apps_smmu 0x481 0>;

			qcom,ee = <0>;
			qcom,num-ees = <4>;
			num-channels = <20>;
			qcom,controlled-remotely;
		};

		tcsr_mutex: hwlock@1f40000 {
			compatible = "qcom,tcsr-mutex";
			reg = <0 0x01f40000 0 0x20000>;

			#hwlock-cells = <1>;
		};

		tcsr: clock-controller@1fc0000 {
			compatible = "qcom,sm7635-tcsr",
				     "syscon";
			reg = <0 0x01fc0000 0 0xa0000>;

			clocks = <&bi_tcxo_div2>;

			#clock-cells = <1>;
			#reset-cells = <1>;
		};

		gpucc: clock-controller@3d90000 {
			compatible = "qcom,sm7635-gpucc";
			reg = <0 0x3d90000 0 0x9800>;

			clocks = <&bi_tcxo_div2>,
				 <&gcc GCC_GPU_GPLL0_CLK_SRC>,
				 <&gcc GCC_GPU_GPLL0_DIV_CLK_SRC>;
			power-domains = <&rpmhpd RPMHPD_CX>;

			#clock-cells = <1>;
			#reset-cells = <1>;
			#power-domain-cells = <1>;
		};

		sdhc_2: mmc@8804000 {
			compatible = "qcom,sm7635-sdhci",
				     "qcom,sdhci-msm-v5";
			reg = <0 0x08804000 0 0x1000>;

			interrupts = <GIC_SPI 204 IRQ_TYPE_LEVEL_HIGH 0>,
				     <GIC_SPI 125 IRQ_TYPE_LEVEL_HIGH 0>;
			interrupt-names = "hc_irq",
					  "pwr_irq";

			clocks = <&gcc GCC_SDCC2_AHB_CLK>,
				 <&gcc GCC_SDCC2_APPS_CLK>,
				 <&rpmhcc RPMH_CXO_CLK>;
			clock-names = "iface",
				      "core",
				      "xo";

			/* TODO: Interconnects */

			power-domains = <&rpmhpd RPMHPD_CX>;
			operating-points-v2 = <&sdhc2_opp_table>;

			iommus = <&apps_smmu 0x540 0>;

			bus-width = <4>;

			qcom,dll-config = <0x0007442c>;
			qcom,ddr-config = <0x80040868>;

			dma-coherent;

			status = "disabled";

			sdhc2_opp_table: opp-table {
				compatible = "operating-points-v2";

				opp-100000000 {
					opp-hz = /bits/ 64 <100000000>;
					required-opps = <&rpmhpd_opp_svs>;
				};

				opp-202000000 {
					opp-hz = /bits/ 64 <202000000>;
					required-opps = <&rpmhpd_opp_svs_l1>;
				};
			};
		};

		videocc: clock-controller@aaf0000 {
			compatible = "qcom,sm7635-videocc";
			reg = <0 0x0aaf0000 0 0x10000>;

			clocks = <&bi_tcxo_div2>,
				 <&bi_tcxo_ao_div2>,
				 <&sleep_clk>;
			power-domains = <&rpmhpd RPMHPD_CX>;

			#clock-cells = <1>;
			#reset-cells = <1>;
			#power-domain-cells = <1>;
		};

		camcc: clock-controller@adb0000 {
			compatible = "qcom,sm7635-camcc";
			reg = <0 0xadb0000 0 0x40000>;

			clocks = <&bi_tcxo_div2>,
				 <&sleep_clk>;
			power-domains = <&rpmhpd RPMHPD_CX>;

			#clock-cells = <1>;
			#reset-cells = <1>;
			#power-domain-cells = <1>;
		};

		dispcc: clock-controller@af00000 {
			compatible = "qcom,sm7635-dispcc";
			reg = <0 0x0af00000 0 0x20000>;

			clocks = <&bi_tcxo_div2>,
				 <&gcc GCC_DISP_GPLL0_DIV_CLK_SRC>,
				 <&sleep_clk>,
				 <0>, /* dsi0 */
				 <0>,
				 <0>, /* dp0 */
				 <0>;

			power-domains = <&rpmhpd RPMHPD_CX>;

			#clock-cells = <1>;
			#reset-cells = <1>;
			#power-domain-cells = <1>;
		};

		usb_1_hsphy: phy@88e3000 {
			compatible = "qcom,sm7635-snps-eusb2-phy",
				     "qcom,sm8550-snps-eusb2-phy";
			reg = <0 0x088e3000 0 0x154>;

			/*clocks = <&tcsr TCSR_USB2_CLKREF_EN>;
			clock-names = "ref";*/

			resets = <&gcc GCC_QUSB2PHY_PRIM_BCR>;

			#phy-cells = <0>;

			status = "disabled";
		};

		pdc: interrupt-controller@b220000 {
			compatible = "qcom,sm7635-pdc",
				     "qcom,pdc";
			reg = <0 0x0b220000 0 0x30000>,
			      <0 0x174000f0 0 0x64>;

			interrupt-parent = <&intc>;

			qcom,pdc-ranges = <0 480 40>, <40 140 11>,
					  <51 527 47>, <98 609 31>,
					  <129 63 1>, <130 716 12>,
				  	  <142 251 5>;

			#interrupt-cells = <2>;
			interrupt-controller;
		};

		tsens0: thermal-sensor@c228000 {
			compatible = "qcom,sm7635-tsens",
				     "qcom,tsens-v2";
			reg = <0 0x0c228000 0 0x1000>, /* TM */
			      <0 0x0c222000 0 0x1000>; /* SROT */

			interrupts = <GIC_SPI 506 IRQ_TYPE_LEVEL_HIGH 0>,
				     <GIC_SPI 640 IRQ_TYPE_LEVEL_HIGH 0>;
			interrupt-names = "uplow",
					  "critical";

			#qcom,sensors = <15>;

			#thermal-sensor-cells = <1>;
		};

		tsens1: thermal-sensor@c229000 {
			compatible = "qcom,sm7635-tsens",
				     "qcom,tsens-v2";
			reg = <0 0x0c229000 0 0x1000>, /* TM */
			      <0 0x0c223000 0 0x1000>; /* SROT */

			interrupts = <GIC_SPI 507 IRQ_TYPE_LEVEL_HIGH 0>,
				     <GIC_SPI 641 IRQ_TYPE_LEVEL_HIGH 0>;
			interrupt-names = "uplow",
					  "critical";

			#qcom,sensors = <16>;

			#thermal-sensor-cells = <1>;
		};

		aoss_qmp: power-management@c300000 {
			compatible = "qcom,sm7635-aoss-qmp",
				     "qcom,aoss-qmp";
			reg = <0 0x0c300000 0 0x400>;

			interrupt-parent = <&ipcc>;
			interrupts-extended = <&ipcc IPCC_CLIENT_AOP IPCC_MPROC_SIGNAL_GLINK_QMP
						     IRQ_TYPE_EDGE_RISING>;

			mboxes = <&ipcc IPCC_CLIENT_AOP IPCC_MPROC_SIGNAL_GLINK_QMP>;

			#clock-cells = <0>;
		};

		sram@c3f0000 {
			compatible = "qcom,rpmh-stats";
			reg = <0 0x0c3f0000 0 0x400>;
		};

		spmi_bus: spmi@c400000 {
			compatible = "qcom,spmi-pmic-arb";
			reg = <0 0x0c400000 0 0x3000>,
			      <0 0x0c500000 0 0x400000>,
			      <0 0x0c440000 0 0x80000>,
			      <0 0x0c4c0000 0 0x20000>,
			      <0 0x0c42d000 0 0x4000>;
			reg-names = "core",
				    "chnls",
				    "obsrvr",
				    "intr",
				    "cnfg";

			interrupts-extended = <&pdc 1 IRQ_TYPE_LEVEL_HIGH>;
			interrupt-names = "periph_irq";

			qcom,ee = <0>;
			qcom,channel = <0>;
			qcom,bus-id = <0>;

			interrupt-controller;
			#interrupt-cells = <4>;

			#address-cells = <2>;
			#size-cells = <0>;
		};

		tlmm: pinctrl@f100000 {
			compatible = "qcom,sm7635-tlmm";
			reg = <0 0x0f100000 0 0x300000>;

			interrupts = <GIC_SPI 208 IRQ_TYPE_LEVEL_HIGH 0>;

			gpio-controller;
			#gpio-cells = <2>;

			interrupt-controller;
			#interrupt-cells = <2>;

			gpio-ranges = <&tlmm 0 0 168>;

			wakeup-parent = <&pdc>;

			pcie0_default_state: pcie0-default-state {
				perst-pins {
					pins = "gpio66";
					function = "gpio";
					drive-strength = <2>;
					bias-pull-down;
				};

				clkreq-pins {
					pins = "gpio67";
					function = "pcie0_clk_req_n";
					drive-strength = <2>;
					bias-pull-up;
				};

				wake-pins {
					pins = "gpio68";
					function = "gpio";
					drive-strength = <2>;
					bias-pull-up;
				};
			};

			qup_i2c0_data_clk: qup-i2c0-data-clk-state {
				pins = "gpio0", "gpio1";
				function = "qup0_se0";
				drive-strength = <2>;
				bias-pull-up;
			};

			qup_i2c1_data_clk: qup-i2c1-data-clk-state {
				pins = "gpio4", "gpio5";
				function = "qup0_se1";
				drive-strength = <2>;
				bias-pull-up;
			};

			qup_i2c2_data_clk: qup-i2c2-data-clk-state {
				pins = "gpio8", "gpio9";
				function = "qup0_se2";
				drive-strength = <2>;
				bias-pull-up;
			};

			qup_i2c3_data_clk: qup-i2c3-data-clk-state {
				pins = "gpio15", "gpio16";
				function = "qup0_se3";
				drive-strength = <2>;
				bias-pull-up;
			};

			qup_i2c4_data_clk: qup-i2c4-data-clk-state {
				pins = "gpio19", "gpio20";
				function = "qup0_se4";
				drive-strength = <2>;
				bias-pull-up;
			};

			qup_i2c6_data_clk: qup-i2c6-data-clk-state {
				pins = "gpio27", "gpio28";
				function = "qup0_se6";
				drive-strength = <2>;
				bias-pull-up;
			};

			qup_i2c7_data_clk: qup-i2c7-data-clk-state {
				pins = "gpio32", "gpio33";
				function = "qup1_se0";
				drive-strength = <2>;
				bias-pull-up;
			};

			qup_i2c8_data_clk: qup-i2c8-data-clk-state {
				pins = "gpio36", "gpio37";
				function = "qup1_se1";
				drive-strength = <2>;
				bias-pull-up;
			};

			qup_i2c9_data_clk: qup-i2c9-data-clk-state {
				pins = "gpio40", "gpio41";
				function = "qup1_se2";
				drive-strength = <2>;
				bias-pull-up;
			};

			qup_i2c10_data_clk: qup-i2c10-data-clk-state {
				pins = "gpio92", "gpio93";
				function = "qup1_se3";
				drive-strength = <2>;
				bias-pull-up;
			};

			qup_i2c12_data_clk: qup-i2c12-data-clk-state {
				pins = "gpio55", "gpio56";
				function = "qup1_se5";
				drive-strength = <2>;
				bias-pull-up;
			};

			qup_i2c13_data_clk: qup-i2c13-data-clk-state {
				pins = "gpio59", "gpio60";
				function = "qup1_se6";
				drive-strength = <2>;
				bias-pull-up;
			};

			qup_spi0_cs: qup-spi0-cs-state {
				pins = "gpio3";
				function = "qup0_se0";
				drive-strength = <6>;
				bias-disable;
			};

			qup_spi0_data_clk: qup-spi0-data-clk-state {
				pins = "gpio0", "gpio1", "gpio2";
				function = "qup0_se0";
				drive-strength = <6>;
				bias-disable;
			};

			qup_spi1_cs: qup-spi1-cs-state {
				pins = "gpio7";
				function = "qup0_se1";
				drive-strength = <6>;
				bias-disable;
			};

			qup_spi1_data_clk: qup-spi1-data-clk-state {
				pins = "gpio4", "gpio5", "gpio6";
				function = "qup0_se1";
				drive-strength = <6>;
				bias-disable;
			};

			qup_spi2_cs: qup-spi2-cs-state {
				pins = "gpio11";
				function = "qup0_se2";
				drive-strength = <6>;
				bias-disable;
			};

			qup_spi2_data_clk: qup-spi2-data-clk-state {
				pins = "gpio8", "gpio9", "gpio10";
				function = "qup0_se2";
				drive-strength = <6>;
				bias-disable;
			};

			qup_spi3_cs: qup-spi3-cs-state {
				pins = "gpio18";
				function = "qup0_se3";
				drive-strength = <6>;
				bias-disable;
			};

			qup_spi3_data_clk: qup-spi3-data-clk-state {
				pins = "gpio15", "gpio16", "gpio17";
				function = "qup0_se3";
				drive-strength = <6>;
				bias-disable;
			};

			qup_spi4_cs: qup-spi4-cs-state {
				pins = "gpio22";
				function = "qup0_se4";
				drive-strength = <6>;
				bias-disable;
			};

			qup_spi4_data_clk: qup-spi4-data-clk-state {
				pins = "gpio19", "gpio20", "gpio21";
				function = "qup0_se4";
				drive-strength = <6>;
				bias-disable;
			};

			qup_spi6_cs: qup-spi6-cs-state {
				pins = "gpio30";
				function = "qup1_se6";
				drive-strength = <6>;
				bias-disable;
			};

			qup_spi6_data_clk: qup-spi6-data-clk-state {
				pins = "gpio27", "gpio28", "gpio29";
				function = "qup0_se6";
				drive-strength = <6>;
				bias-disable;
			};

			qup_spi7_cs: qup-spi7-cs-state {
				pins = "gpio95";
				function = "qup1_se0";
				drive-strength = <6>;
				bias-disable;
			};

			qup_spi7_data_clk: qup-spi7-data-clk-state {
				pins = "gpio32", "gpio33", "gpio94";
				function = "qup1_se0";
				drive-strength = <6>;
				bias-disable;
			};

			qup_spi8_cs: qup-spi8-cs-state {
				pins = "gpio39";
				function = "qup1_se1";
				drive-strength = <6>;
				bias-disable;
			};

			qup_spi8_data_clk: qup-spi8-data-clk-state {
				pins = "gpio36", "gpio37", "gpio38";
				function = "qup1_se1";
				drive-strength = <6>;
				bias-disable;
			};

			qup_spi9_cs: qup-spi9-cs-state {
				pins = "gpio43";
				function = "qup1_se2";
				drive-strength = <6>;
				bias-disable;
			};

			qup_spi9_data_clk: qup-spi9-data-clk-state {
				pins = "gpio40", "gpio41", "gpio42";
				function = "qup1_se2";
				drive-strength = <6>;
				bias-disable;
			};

			qup_spi10_cs: qup-spi10-cs-state {
				pins = "gpio95";
				function = "qup1_se3";
				drive-strength = <6>;
				bias-disable;
			};

			qup_spi10_data_clk: qup-spi10-data-clk-state {
				pins = "gpio92", "gpio93", "gpio94";
				function = "qup1_se3";
				drive-strength = <6>;
				bias-disable;
			};

			qup_spi12_cs: qup-spi12-cs-state {
				pins = "gpio60";
				function = "qup1_se5";
				drive-strength = <6>;
				bias-disable;
			};

			qup_spi12_data_clk: qup-spi12-data-clk-state {
				pins = "gpio55", "gpio56", "gpio59";
				function = "qup1_se5";
				drive-strength = <6>;
				bias-disable;
			};

			qup_spi13_cs: qup-spi13-cs-state {
				pins = "gpio60";
				function = "qup1_se6";
				drive-strength = <6>;
				bias-disable;
			};

			qup_spi13_data_clk: qup-spi13-data-clk-state {
				pins = "gpio55", "gpio56", "gpio59";
				function = "qup1_se6";
				drive-strength = <6>;
				bias-disable;
			};

			qup_uart5_default: qup-uart5-default-state {
				pins = "gpio25", "gpio26";
				function = "qup0_se5";
				drive-strength = <2>;
				bias-disable;
			};

			qup_uart11_default: qup-uart11-default-state {
				pins = "gpio50", "gpio51";
				function = "qup1_se4";
				drive-strength = <2>;
				bias-pull-up;
			};

			qup_uart11_cts_rts: qup-uart11-cts-rts-state {
				pins = "gpio48", "gpio49";
				function = "qup1_se4";
				drive-strength = <2>;
				bias-pull-down;
			};

			sdc2_sleep: sdc2-sleep-state {
				clk-pins {
					pins = "sdc2_clk";
					drive-strength = <2>;
					bias-disable;
				};

				cmd-pins {
					pins = "sdc2_cmd";
					drive-strength = <2>;
					bias-pull-up;
				};

				data-pins {
					pins = "sdc2_data";
					drive-strength = <2>;
					bias-pull-up;
				};
			};

			sdc2_default: sdc2-default-state {
				clk-pins {
					pins = "sdc2_clk";
					drive-strength = <16>;
					bias-disable;
				};

				cmd-pins {
					pins = "sdc2_cmd";
					drive-strength = <10>;
					bias-pull-up;
				};

				data-pins {
					pins = "sdc2_data";
					drive-strength = <10>;
					bias-pull-up;
				};
			};
		};

		apps_smmu: iommu@15000000 {
			compatible = "qcom,sm7635-smmu-500",
				     "qcom,smmu-500",
				     "arm,mmu-500";
			reg = <0 0x15000000 0 0x100000>;

			interrupts = <GIC_SPI 65 IRQ_TYPE_LEVEL_HIGH 0>,
				     <GIC_SPI 97 IRQ_TYPE_LEVEL_HIGH 0>,
				     <GIC_SPI 98 IRQ_TYPE_LEVEL_HIGH 0>,
				     <GIC_SPI 99 IRQ_TYPE_LEVEL_HIGH 0>,
				     <GIC_SPI 100 IRQ_TYPE_LEVEL_HIGH 0>,
				     <GIC_SPI 101 IRQ_TYPE_LEVEL_HIGH 0>,
				     <GIC_SPI 102 IRQ_TYPE_LEVEL_HIGH 0>,
				     <GIC_SPI 103 IRQ_TYPE_LEVEL_HIGH 0>,
				     <GIC_SPI 104 IRQ_TYPE_LEVEL_HIGH 0>,
				     <GIC_SPI 105 IRQ_TYPE_LEVEL_HIGH 0>,
				     <GIC_SPI 106 IRQ_TYPE_LEVEL_HIGH 0>,
				     <GIC_SPI 107 IRQ_TYPE_LEVEL_HIGH 0>,
				     <GIC_SPI 108 IRQ_TYPE_LEVEL_HIGH 0>,
				     <GIC_SPI 109 IRQ_TYPE_LEVEL_HIGH 0>,
				     <GIC_SPI 110 IRQ_TYPE_LEVEL_HIGH 0>,
				     <GIC_SPI 111 IRQ_TYPE_LEVEL_HIGH 0>,
				     <GIC_SPI 112 IRQ_TYPE_LEVEL_HIGH 0>,
				     <GIC_SPI 113 IRQ_TYPE_LEVEL_HIGH 0>,
				     <GIC_SPI 114 IRQ_TYPE_LEVEL_HIGH 0>,
				     <GIC_SPI 115 IRQ_TYPE_LEVEL_HIGH 0>,
				     <GIC_SPI 116 IRQ_TYPE_LEVEL_HIGH 0>,
				     <GIC_SPI 117 IRQ_TYPE_LEVEL_HIGH 0>,
				     <GIC_SPI 118 IRQ_TYPE_LEVEL_HIGH 0>,
				     <GIC_SPI 181 IRQ_TYPE_LEVEL_HIGH 0>,
				     <GIC_SPI 182 IRQ_TYPE_LEVEL_HIGH 0>,
				     <GIC_SPI 183 IRQ_TYPE_LEVEL_HIGH 0>,
				     <GIC_SPI 184 IRQ_TYPE_LEVEL_HIGH 0>,
				     <GIC_SPI 185 IRQ_TYPE_LEVEL_HIGH 0>,
				     <GIC_SPI 186 IRQ_TYPE_LEVEL_HIGH 0>,
				     <GIC_SPI 187 IRQ_TYPE_LEVEL_HIGH 0>,
				     <GIC_SPI 188 IRQ_TYPE_LEVEL_HIGH 0>,
				     <GIC_SPI 189 IRQ_TYPE_LEVEL_HIGH 0>,
				     <GIC_SPI 190 IRQ_TYPE_LEVEL_HIGH 0>,
				     <GIC_SPI 191 IRQ_TYPE_LEVEL_HIGH 0>,
				     <GIC_SPI 192 IRQ_TYPE_LEVEL_HIGH 0>,
				     <GIC_SPI 315 IRQ_TYPE_LEVEL_HIGH 0>,
				     <GIC_SPI 316 IRQ_TYPE_LEVEL_HIGH 0>,
				     <GIC_SPI 317 IRQ_TYPE_LEVEL_HIGH 0>,
				     <GIC_SPI 318 IRQ_TYPE_LEVEL_HIGH 0>,
				     <GIC_SPI 319 IRQ_TYPE_LEVEL_HIGH 0>,
				     <GIC_SPI 320 IRQ_TYPE_LEVEL_HIGH 0>,
				     <GIC_SPI 321 IRQ_TYPE_LEVEL_HIGH 0>,
				     <GIC_SPI 322 IRQ_TYPE_LEVEL_HIGH 0>,
				     <GIC_SPI 323 IRQ_TYPE_LEVEL_HIGH 0>,
				     <GIC_SPI 324 IRQ_TYPE_LEVEL_HIGH 0>,
				     <GIC_SPI 325 IRQ_TYPE_LEVEL_HIGH 0>,
				     <GIC_SPI 326 IRQ_TYPE_LEVEL_HIGH 0>,
				     <GIC_SPI 327 IRQ_TYPE_LEVEL_HIGH 0>,
				     <GIC_SPI 328 IRQ_TYPE_LEVEL_HIGH 0>,
				     <GIC_SPI 329 IRQ_TYPE_LEVEL_HIGH 0>,
				     <GIC_SPI 330 IRQ_TYPE_LEVEL_HIGH 0>,
				     <GIC_SPI 331 IRQ_TYPE_LEVEL_HIGH 0>,
				     <GIC_SPI 332 IRQ_TYPE_LEVEL_HIGH 0>,
				     <GIC_SPI 333 IRQ_TYPE_LEVEL_HIGH 0>,
				     <GIC_SPI 334 IRQ_TYPE_LEVEL_HIGH 0>,
				     <GIC_SPI 335 IRQ_TYPE_LEVEL_HIGH 0>,
				     <GIC_SPI 336 IRQ_TYPE_LEVEL_HIGH 0>,
				     <GIC_SPI 337 IRQ_TYPE_LEVEL_HIGH 0>,
				     <GIC_SPI 338 IRQ_TYPE_LEVEL_HIGH 0>,
				     <GIC_SPI 339 IRQ_TYPE_LEVEL_HIGH 0>,
				     <GIC_SPI 340 IRQ_TYPE_LEVEL_HIGH 0>,
				     <GIC_SPI 341 IRQ_TYPE_LEVEL_HIGH 0>,
				     <GIC_SPI 342 IRQ_TYPE_LEVEL_HIGH 0>,
				     <GIC_SPI 343 IRQ_TYPE_LEVEL_HIGH 0>,
				     <GIC_SPI 344 IRQ_TYPE_LEVEL_HIGH 0>,
				     <GIC_SPI 345 IRQ_TYPE_LEVEL_HIGH 0>,
				     <GIC_SPI 395 IRQ_TYPE_LEVEL_HIGH 0>,
				     <GIC_SPI 396 IRQ_TYPE_LEVEL_HIGH 0>,
				     <GIC_SPI 397 IRQ_TYPE_LEVEL_HIGH 0>,
				     <GIC_SPI 398 IRQ_TYPE_LEVEL_HIGH 0>,
				     <GIC_SPI 399 IRQ_TYPE_LEVEL_HIGH 0>,
				     <GIC_SPI 400 IRQ_TYPE_LEVEL_HIGH 0>,
				     <GIC_SPI 401 IRQ_TYPE_LEVEL_HIGH 0>,
				     <GIC_SPI 402 IRQ_TYPE_LEVEL_HIGH 0>,
				     <GIC_SPI 403 IRQ_TYPE_LEVEL_HIGH 0>,
				     <GIC_SPI 404 IRQ_TYPE_LEVEL_HIGH 0>,
				     <GIC_SPI 405 IRQ_TYPE_LEVEL_HIGH 0>,
				     <GIC_SPI 406 IRQ_TYPE_LEVEL_HIGH 0>,
				     <GIC_SPI 407 IRQ_TYPE_LEVEL_HIGH 0>,
				     <GIC_SPI 408 IRQ_TYPE_LEVEL_HIGH 0>,
				     <GIC_SPI 409 IRQ_TYPE_LEVEL_HIGH 0>,
				     <GIC_SPI 418 IRQ_TYPE_LEVEL_HIGH 0>,
				     <GIC_SPI 419 IRQ_TYPE_LEVEL_HIGH 0>,
				     <GIC_SPI 412 IRQ_TYPE_LEVEL_HIGH 0>,
				     <GIC_SPI 421 IRQ_TYPE_LEVEL_HIGH 0>,
				     <GIC_SPI 706 IRQ_TYPE_LEVEL_HIGH 0>,
				     <GIC_SPI 423 IRQ_TYPE_LEVEL_HIGH 0>,
				     <GIC_SPI 424 IRQ_TYPE_LEVEL_HIGH 0>,
				     <GIC_SPI 425 IRQ_TYPE_LEVEL_HIGH 0>,
				     <GIC_SPI 689 IRQ_TYPE_LEVEL_HIGH 0>,
				     <GIC_SPI 690 IRQ_TYPE_LEVEL_HIGH 0>,
				     <GIC_SPI 691 IRQ_TYPE_LEVEL_HIGH 0>,
				     <GIC_SPI 692 IRQ_TYPE_LEVEL_HIGH 0>,
				     <GIC_SPI 693 IRQ_TYPE_LEVEL_HIGH 0>,
				     <GIC_SPI 694 IRQ_TYPE_LEVEL_HIGH 0>,
				     <GIC_SPI 695 IRQ_TYPE_LEVEL_HIGH 0>,
				     <GIC_SPI 696 IRQ_TYPE_LEVEL_HIGH 0>;

			#iommu-cells = <2>;
			#global-interrupts = <1>;

			dma-coherent;
		};

		intc: interrupt-controller@17100000 {
			compatible = "arm,gic-v3";
			reg = <0 0x17100000 0 0x10000>,		/* GICD */
			      <0 0x17180000 0 0x200000>;	/* GICR * 8 */

			interrupts = <GIC_PPI 9 IRQ_TYPE_LEVEL_LOW 0>;

			#interrupt-cells = <4>;
			interrupt-controller;

			#address-cells = <2>;
			#size-cells = <2>;
			ranges;

			ppi-partitions {
				ppi_cluster0: interrupt-partition-0 {
					affinity = <&cpu0 &cpu1 &cpu2 &cpu3>;
				};

				ppi_cluster1: interrupt-partition-1 {
					affinity = <&cpu4 &cpu5 &cpu6>;
				};

				ppi_cluster2: interrupt-partition-2 {
					affinity = <&cpu7>;
				};
			};

			gic_its: msi-controller@17140000 {
				compatible = "arm,gic-v3-its";
				reg = <0 0x17140000 0 0x20000>;

				msi-controller;
				#msi-cells = <1>;
			};
		};

		timer@17420000 {
			compatible = "arm,armv7-timer-mem";
			reg = <0 0x17420000 0 0x1000>;

			ranges = <0 0 0 0x20000000>;
			#address-cells = <1>;
			#size-cells = <1>;

			frame@17421000 {
				reg = <0x17421000 0x1000>,
				      <0x17422000 0x1000>;

				interrupts = <GIC_SPI 8 IRQ_TYPE_LEVEL_HIGH 0>,
					     <GIC_SPI 6 IRQ_TYPE_LEVEL_HIGH 0>;

				frame-number = <0>;
			};

			frame@17423000 {
				reg = <0x17423000 0x1000>;

				interrupts = <GIC_SPI 9 IRQ_TYPE_LEVEL_HIGH 0>;

				frame-number = <1>;

				status = "disabled";
			};

			frame@17425000 {
				reg = <0x17425000 0x1000>;

				interrupts = <GIC_SPI 10 IRQ_TYPE_LEVEL_HIGH 0>;

				frame-number = <2>;

				status = "disabled";
			};

			frame@17427000 {
				reg = <0x17427000 0x1000>;

				interrupts = <GIC_SPI 11 IRQ_TYPE_LEVEL_HIGH 0>;

				frame-number = <3>;

				status = "disabled";
			};

			frame@17429000 {
				reg = <0x17429000 0x1000>;

				interrupts = <GIC_SPI 12 IRQ_TYPE_LEVEL_HIGH 0>;

				frame-number = <4>;

				status = "disabled";
			};

			frame@1742b000 {
				reg = <0x1742b000 0x1000>;

				interrupts = <GIC_SPI 13 IRQ_TYPE_LEVEL_HIGH 0>;

				frame-number = <5>;

				status = "disabled";
			};

			frame@1742d000 {
				reg = <0x1742d000 0x1000>;

				interrupts = <GIC_SPI 14 IRQ_TYPE_LEVEL_HIGH 0>;

				frame-number = <6>;

				status = "disabled";
			};
		};

		apps_rsc: rsc@17a00000 {
			compatible = "qcom,rpmh-rsc";
			reg = <0 0x17a00000 0 0x10000>,
			      <0 0x17a10000 0 0x10000>,
			      <0 0x17a20000 0 0x10000>;
			reg-names = "drv-0",
				    "drv-1",
				    "drv-2";

			interrupts = <GIC_SPI 3 IRQ_TYPE_LEVEL_HIGH 0>,
				     <GIC_SPI 4 IRQ_TYPE_LEVEL_HIGH 0>,
				     <GIC_SPI 5 IRQ_TYPE_LEVEL_HIGH 0>;

			power-domains = <&cluster_pd>;

			qcom,tcs-offset = <0xd00>;
			qcom,drv-id = <2>;
			qcom,tcs-config = <ACTIVE_TCS    3>, <SLEEP_TCS     2>,
					  <WAKE_TCS      2>, <CONTROL_TCS   0>;

			label = "apps_rsc";

			apps_bcm_voter: bcm-voter {
				compatible = "qcom,bcm-voter";
			};

			rpmhcc: clock-controller {
				compatible = "qcom,sm7635-rpmh-clk";

				clocks = <&xo_board>;
				clock-names = "xo";

				#clock-cells = <1>;
			};

			rpmhpd: power-controller {
				compatible = "qcom,sm7635-rpmhpd";

				operating-points-v2 = <&rpmhpd_opp_table>;

				#power-domain-cells = <1>;

				rpmhpd_opp_table: opp-table {
					compatible = "operating-points-v2";

					rpmhpd_opp_ret: opp-16 {
						opp-level = <RPMH_REGULATOR_LEVEL_RETENTION>;
					};

					rpmhpd_opp_min_svs: opp-48 {
						opp-level = <RPMH_REGULATOR_LEVEL_MIN_SVS>;
					};

					rpmhpd_opp_low_svs_d2: opp-52 {
						opp-level = <RPMH_REGULATOR_LEVEL_LOW_SVS_D2>;
					};

					rpmhpd_opp_low_svs_d1: opp-56 {
						opp-level = <RPMH_REGULATOR_LEVEL_LOW_SVS_D1>;
					};

					rpmhpd_opp_low_svs_d0: opp-60 {
						opp-level = <RPMH_REGULATOR_LEVEL_LOW_SVS_D0>;
					};

					rpmhpd_opp_low_svs: opp-64 {
						opp-level = <RPMH_REGULATOR_LEVEL_LOW_SVS>;
					};

					rpmhpd_opp_low_svs_l1: opp-80 {
						opp-level = <RPMH_REGULATOR_LEVEL_LOW_SVS_L1>;
					};

					rpmhpd_opp_svs: opp-128 {
						opp-level = <RPMH_REGULATOR_LEVEL_SVS>;
					};

					rpmhpd_opp_svs_l0: opp-144 {
						opp-level = <RPMH_REGULATOR_LEVEL_SVS_L0>;
					};

					rpmhpd_opp_svs_l1: opp-192 {
						opp-level = <RPMH_REGULATOR_LEVEL_SVS_L1>;
					};

					rpmhpd_opp_nom: opp-256 {
						opp-level = <RPMH_REGULATOR_LEVEL_NOM>;
					};

					rpmhpd_opp_nom_l1: opp-320 {
						opp-level = <RPMH_REGULATOR_LEVEL_NOM_L1>;
					};

					rpmhpd_opp_nom_l2: opp-336 {
						opp-level = <RPMH_REGULATOR_LEVEL_NOM_L2>;
					};

					rpmhpd_opp_turbo: opp-384 {
						opp-level = <RPMH_REGULATOR_LEVEL_TURBO>;
					};

					rpmhpd_opp_turbo_l1: opp-416 {
						opp-level = <RPMH_REGULATOR_LEVEL_TURBO_L1>;
					};
				};
			};
		};
        };

	timer {
		compatible = "arm,armv8-timer";

		interrupts = <GIC_PPI 13 (GIC_CPU_MASK_SIMPLE(8) | IRQ_TYPE_LEVEL_LOW)>,
			     <GIC_PPI 14 (GIC_CPU_MASK_SIMPLE(8) | IRQ_TYPE_LEVEL_LOW)>,
			     <GIC_PPI 11 (GIC_CPU_MASK_SIMPLE(8) | IRQ_TYPE_LEVEL_LOW)>,
			     <GIC_PPI 12 (GIC_CPU_MASK_SIMPLE(8) | IRQ_TYPE_LEVEL_LOW)>;
	};
};
